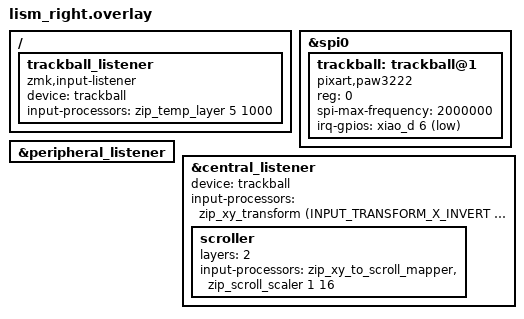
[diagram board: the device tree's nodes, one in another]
&spi0 {
    status = "okay";

    /* ラベル名を 'trackball_central' から 'trackball' に変更します */
    trackball: trackball@1 {
        status = "okay";
        compatible = "pixart,paw3222";
        reg = <0>;
        spi-max-frequency = <2000000>;
        irq-gpios = <&xiao_d 6 (GPIO_ACTIVE_LOW | GPIO_PULL_UP)>;
    };
};

// ペリフェラル（split経由）のリスナーを有効化
&peripheral_listener {
    status = "okay";
};

// セントラルのリスナーを有効化し、deviceを紐付け
&central_listener {
    status = "okay";
    /* ここも &trackball に合わせます */
    device = <&trackball>;
    input-processors = 
        <&zip_xy_transform (INPUT_TRANSFORM_X_INVERT | INPUT_TRANSFORM_Y_INVERT)>;

    scroller {
        layers = <2>;
        input-processors = 
            <&zip_xy_to_scroll_mapper>,
            <&zip_scroll_scaler 1 16>;
    };
};

/* オートマウスレイヤーの設定を追加したい場合はここに追記 */
/ {
    trackball_listener {
        compatible = "zmk,input-listener";
        device = <&trackball>;
        input-processors = <&zip_temp_layer 5 1000>;
    };
};
